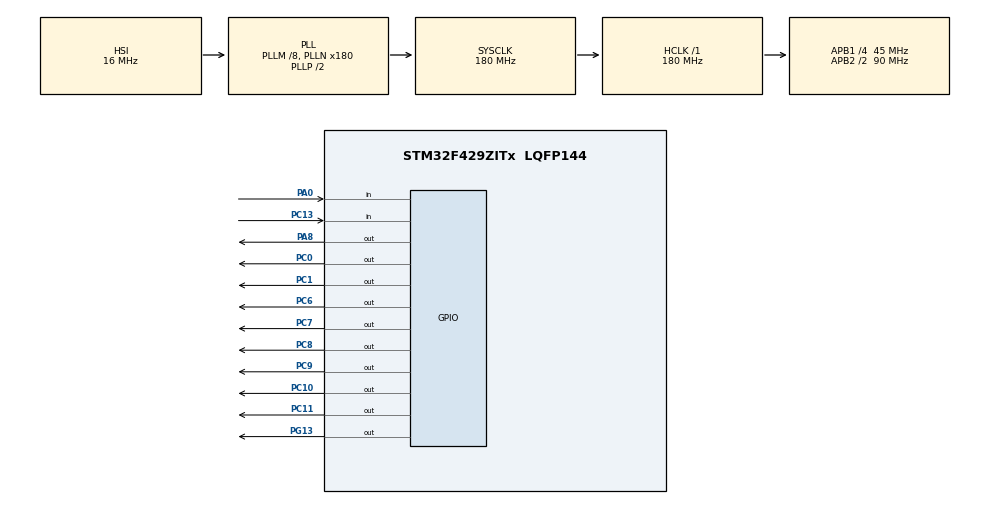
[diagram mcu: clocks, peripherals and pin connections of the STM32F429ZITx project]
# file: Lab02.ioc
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Mcu.Family=STM32F4
Mcu.Name=STM32F429ZITx
Mcu.Package=LQFP144
NVIC.PriorityGroup=NVIC_PRIORITYGROUP_4
PA0/WKUP.Signal=GPIO_Input
PA8.GPIO_ModeDefaultOutputPP=GPIO_MODE_OUTPUT_PP
PA8.PinState=GPIO_PIN_RESET
PA8.Signal=GPIO_Output
PC0.Signal=GPIO_Output
PC1.Signal=GPIO_Output
PC10.PinState=GPIO_PIN_RESET
PC10.Signal=GPIO_Output
PC11.PinState=GPIO_PIN_RESET
PC11.Signal=GPIO_Output
PC13.GPIO_PuPd=GPIO_NOPULL
PC13.Signal=GPIO_Input
PC6.PinState=GPIO_PIN_RESET
PC6.Signal=GPIO_Output
PC7.PinState=GPIO_PIN_RESET
PC7.Signal=GPIO_Output
PC8.GPIO_PuPd=GPIO_NOPULL
PC8.PinState=GPIO_PIN_RESET
PC8.Signal=GPIO_Output
PC9.PinState=GPIO_PIN_RESET
PC9.Signal=GPIO_Output
PG13.GPIO_PuPd=GPIO_NOPULL
PG13.Signal=GPIO_Output
ProjectManager.HeapSize=0x200
ProjectManager.StackSize=0x400
ProjectManager.TargetToolchain=STM32CubeIDE
RCC.48MHZClocksFreq_Value=90000000
RCC.AHBFreq_Value=180000000
RCC.APB1CLKDivider=RCC_HCLK_DIV4
RCC.APB1Freq_Value=45000000
RCC.APB1TimFreq_Value=90000000
RCC.APB2CLKDivider=RCC_HCLK_DIV2
RCC.APB2Freq_Value=90000000
RCC.APB2TimFreq_Value=180000000
RCC.CortexFreq_Value=180000000
RCC.HCLKFreq_Value=180000000
RCC.HSE_VALUE=25000000
RCC.HSI_VALUE=16000000
RCC.LSE_VALUE=32768
RCC.PLLM=8
RCC.PLLN=180
RCC.SYSCLKFreq_VALUE=180000000
RCC.SYSCLKSource=RCC_SYSCLKSOURCE_PLLCLK
RCC.VCOOutputFreq_Value=360000000
board=custom

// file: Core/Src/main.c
/* USER CODE BEGIN Header */
/**
  ******************************************************************************
  * @file           : main.c
  * @brief          : Main program body
  ******************************************************************************
  * @attention
  *
  * <h2><center>&copy; Copyright (c) 2021 STMicroelectronics.
  * All rights reserved.</center></h2>
  *
  * This software component is licensed by ST under BSD 3-Clause license,
  * the "License"; You may not use this file except in compliance with the
  * License. You may obtain a copy of the License at:
  *                        opensource.org/licenses/BSD-3-Clause
  *
  ******************************************************************************
  */
/* USER CODE END Header */
#include "main.h"
#include "gpio.h"

void SystemClock_Config(void);

/* USER CODE BEGIN 0 */
uint8_t num = 0;
uint8_t n = 0;
/* USER CODE END 0 */

int main(void)
{

  /* MCU Configuration--------------------------------------------------------*/

  /* Reset of all peripherals, Initializes the Flash interface and the Systick. */
  HAL_Init();

  /* Configure the system clock */
  SystemClock_Config();

  /* Initialize all configured peripherals */
  MX_GPIO_Init();
  /* USER CODE BEGIN 2 */
  HAL_GPIO_WritePin(GPIOC, GPIO_PIN_0|GPIO_PIN_1|GPIO_PIN_6|GPIO_PIN_7
                              |GPIO_PIN_8|GPIO_PIN_9|GPIO_PIN_10|GPIO_PIN_11, GPIO_PIN_SET);
  /* USER CODE END 2 */

  /* Infinite loop */
  while (1)
  {

    /* USER CODE BEGIN 3 */
//	  /* LAB1-3 */
//	  if(HAL_GPIO_ReadPin(GPIOC,GPIO_PIN_13) == GPIO_PIN_RESET){
//		  /*turn LED Pin8 ON*/
//		  HAL_GPIO_WritePin(GPIOC,GPIO_PIN_8,GPIO_PIN_RESET);
//		  /*check LED Pin8 ON*/
//		  if(HAL_GPIO_ReadPin(GPIOC,GPIO_PIN_8) == GPIO_PIN_RESET){
//			  HAL_GPIO_WritePin(GPIOC,GPIO_PIN_0,GPIO_PIN_RESET);
//		  }
//		  HAL_Delay(1000);
//		  /*turn LED Pin8 OFF*/
//		  HAL_GPIO_WritePin(GPIOC,GPIO_PIN_8,GPIO_PIN_SET);
//		  /*check LED Pin8 OFF*/
//		  if(HAL_GPIO_ReadPin(GPIOC,GPIO_PIN_8) == GPIO_PIN_SET){
//		  			  HAL_GPIO_WritePin(GPIOC,GPIO_PIN_0,GPIO_PIN_SET);
//		  }
//	  }

//	  /* LAB4 */
//	  if(HAL_GPIO_ReadPin(GPIOA,GPIO_PIN_0) == GPIO_PIN_SET){
//		  if(num == 8){
//			  num = 0;
//		  }
//		  num++;
//		  HAL_Delay(500);
//	  }
//	  	  	  if(num == 0)
//	  	  	  	  	  {
//	  	  		HAL_GPIO_WritePin(GPIOC,GPIO_PIN_0,GPIO_PIN_SET);
//	  	  	    HAL_GPIO_WritePin(GPIOC,GPIO_PIN_1,GPIO_PIN_SET);
//	  	  		HAL_GPIO_WritePin(GPIOC,GPIO_PIN_6,GPIO_PIN_SET);
//	  	  	    HAL_GPIO_WritePin(GPIOC,GPIO_PIN_7,GPIO_PIN_SET);
//	  	  	    HAL_GPIO_WritePin(GPIOC,GPIO_PIN_8,GPIO_PIN_SET);
//	  	        HAL_GPIO_WritePin(GPIOC,GPIO_PIN_9,GPIO_PIN_SET);
//	  	  	    HAL_GPIO_WritePin(GPIOC,GPIO_PIN_10,GPIO_PIN_SET);
//	  	  	    HAL_GPIO_WritePin(GPIOC,GPIO_PIN_11,GPIO_PIN_SET);
//	  	  	  	  	  }
//
//	  	  	  if(num == 1)
//	  		  	  	  {
//	  			  HAL_GPIO_WritePin(GPIOC,GPIO_PIN_11,GPIO_PIN_RESET);
//	  			  HAL_GPIO_WritePin(GPIOC,GPIO_PIN_0,GPIO_PIN_SET);
//	  		  	  	  }
//	  		  if(num == 2)
//	  		  		  {
//	  			  HAL_GPIO_WritePin(GPIOC,GPIO_PIN_10,GPIO_PIN_RESET);
//	  			  HAL_GPIO_WritePin(GPIOC,GPIO_PIN_11,GPIO_PIN_SET);
//	  		  		  }
//	  		  if(num == 3)
//	  		  		  {
//	  			  HAL_GPIO_WritePin(GPIOC,GPIO_PIN_9,GPIO_PIN_RESET);
//	  			  HAL_GPIO_WritePin(GPIOC,GPIO_PIN_10,GPIO_PIN_SET);
//	  		  		  }
//	  		  if(num == 4)
//	  		  		  {
//	  			  HAL_GPIO_WritePin(GPIOC,GPIO_PIN_8,GPIO_PIN_RESET);
//	  			  HAL_GPIO_WritePin(GPIOC,GPIO_PIN_9,GPIO_PIN_SET);
//	  		  		  }
//	  		  if(num == 5)
//	  		  		  {
//	  			  HAL_GPIO_WritePin(GPIOC,GPIO_PIN_7,GPIO_PIN_RESET);
//	  			  HAL_GPIO_WritePin(GPIOC,GPIO_PIN_8,GPIO_PIN_SET);
//	  		  		  }
//	  		  if(num == 6)
//	  		  		  {
//	  			  HAL_GPIO_WritePin(GPIOC,GPIO_PIN_6,GPIO_PIN_RESET);
//	  			  HAL_GPIO_WritePin(GPIOC,GPIO_PIN_7,GPIO_PIN_SET);
//	  		  		  }
//	  		  if(num == 7)
//	  		  		  {
//	  			  HAL_GPIO_WritePin(GPIOC,GPIO_PIN_1,GPIO_PIN_RESET);
//	  			  HAL_GPIO_WritePin(GPIOC,GPIO_PIN_6,GPIO_PIN_SET);
//	  		   		  }
//	  		  if(num == 8)
//	  		  		  {
//	  			  HAL_GPIO_WritePin(GPIOC,GPIO_PIN_1,GPIO_PIN_SET);
//	  			  HAL_GPIO_WritePin(GPIOC,GPIO_PIN_0,GPIO_PIN_RESET);
//	  			  	  }
//	  		if(HAL_GPIO_ReadPin(GPIOC,GPIO_PIN_13) == GPIO_PIN_RESET){
//	  		HAL_GPIO_WritePin(GPIOC,GPIO_PIN_0,GPIO_PIN_RESET);
//	  	    HAL_GPIO_WritePin(GPIOC,GPIO_PIN_1,GPIO_PIN_SET);
//	  		HAL_GPIO_WritePin(GPIOC,GPIO_PIN_6,GPIO_PIN_SET);
//	  		HAL_GPIO_WritePin(GPIOC,GPIO_PIN_7,GPIO_PIN_SET);
//	  		HAL_GPIO_WritePin(GPIOC,GPIO_PIN_8,GPIO_PIN_SET);
//	  		HAL_GPIO_WritePin(GPIOC,GPIO_PIN_9,GPIO_PIN_SET);
//	  	    HAL_GPIO_WritePin(GPIOC,GPIO_PIN_10,GPIO_PIN_SET);
//	  		HAL_GPIO_WritePin(GPIOC,GPIO_PIN_11,GPIO_PIN_SET);
//	  		HAL_Delay(500);
//	  		HAL_GPIO_WritePin(GPIOC,GPIO_PIN_1,GPIO_PIN_RESET);
//	  		HAL_GPIO_WritePin(GPIOC,GPIO_PIN_0,GPIO_PIN_SET);
//	  		HAL_Delay(500);
//	  		HAL_GPIO_WritePin(GPIOC,GPIO_PIN_6,GPIO_PIN_RESET);
//	  		HAL_GPIO_WritePin(GPIOC,GPIO_PIN_1,GPIO_PIN_SET);
//	  		HAL_Delay(500);
//	  		HAL_GPIO_WritePin(GPIOC,GPIO_PIN_7,GPIO_PIN_RESET);
//	  		HAL_GPIO_WritePin(GPIOC,GPIO_PIN_6,GPIO_PIN_SET);
//	  		HAL_Delay(500);
//	  		HAL_GPIO_WritePin(GPIOC,GPIO_PIN_8,GPIO_PIN_RESET);
//	  		HAL_GPIO_WritePin(GPIOC,GPIO_PIN_7,GPIO_PIN_SET);
//	  		HAL_Delay(500);
//	  		HAL_GPIO_WritePin(GPIOC,GPIO_PIN_9,GPIO_PIN_RESET);
//	  		HAL_GPIO_WritePin(GPIOC,GPIO_PIN_8,GPIO_PIN_SET);
//	  		HAL_Delay(500);
//	  		HAL_GPIO_WritePin(GPIOC,GPIO_PIN_10,GPIO_PIN_RESET);
//	  		HAL_GPIO_WritePin(GPIOC,GPIO_PIN_9,GPIO_PIN_SET);
//	  		HAL_Delay(500);
//	  		HAL_GPIO_WritePin(GPIOC,GPIO_PIN_10,GPIO_PIN_SET);
//	  		HAL_GPIO_WritePin(GPIOC,GPIO_PIN_11,GPIO_PIN_RESET);
//	  		HAL_Delay(500);
//	  		num = 0;
//	  		  }
//
//	  for(n=0;n<=2;n++){
//		  GPIOC -> BSRR = 0x07000000;
//		  HAL_Delay(500);
//		  GPIOC -> BSRR = 0x00000400 >> n;
//		  HAL_Delay(500);
//	  }
	  GPIOC -> BSRR = 0x07000000;
	  HAL_Delay(500);
	  GPIOC -> BSRR = 0x00000700;
	  HAL_Delay(500);
  }

  /* USER CODE END 3 */
}

void SystemClock_Config(void)
{
  RCC_OscInitTypeDef RCC_OscInitStruct = {0};
  RCC_ClkInitTypeDef RCC_ClkInitStruct = {0};

  /** Configure the main internal regulator output voltage
  */
  __HAL_RCC_PWR_CLK_ENABLE();
  __HAL_PWR_VOLTAGESCALING_CONFIG(PWR_REGULATOR_VOLTAGE_SCALE1);
  /** Initializes the RCC Oscillators according to the specified parameters
  * in the RCC_OscInitTypeDef structure.
  */
  RCC_OscInitStruct.OscillatorType = RCC_OSCILLATORTYPE_HSI;
  RCC_OscInitStruct.HSIState = RCC_HSI_ON;
  RCC_OscInitStruct.HSICalibrationValue = RCC_HSICALIBRATION_DEFAULT;
  RCC_OscInitStruct.PLL.PLLState = RCC_PLL_ON;
  RCC_OscInitStruct.PLL.PLLSource = RCC_PLLSOURCE_HSI;
  RCC_OscInitStruct.PLL.PLLM = 8;
  RCC_OscInitStruct.PLL.PLLN = 180;
  RCC_OscInitStruct.PLL.PLLP = RCC_PLLP_DIV2;
  RCC_OscInitStruct.PLL.PLLQ = 4;
  if (HAL_RCC_OscConfig(&RCC_OscInitStruct) != HAL_OK)
  {
    Error_Handler();
  }
  /** Activate the Over-Drive mode
  */
  if (HAL_PWREx_EnableOverDrive() != HAL_OK)
  {
    Error_Handler();
  }
  /** Initializes the CPU, AHB and APB buses clocks
  */
  RCC_ClkInitStruct.ClockType = RCC_CLOCKTYPE_HCLK|RCC_CLOCKTYPE_SYSCLK
                              |RCC_CLOCKTYPE_PCLK1|RCC_CLOCKTYPE_PCLK2;
  RCC_ClkInitStruct.SYSCLKSource = RCC_SYSCLKSOURCE_PLLCLK;
  RCC_ClkInitStruct.AHBCLKDivider = RCC_SYSCLK_DIV1;
  RCC_ClkInitStruct.APB1CLKDivider = RCC_HCLK_DIV4;
  RCC_ClkInitStruct.APB2CLKDivider = RCC_HCLK_DIV2;

  if (HAL_RCC_ClockConfig(&RCC_ClkInitStruct, FLASH_LATENCY_5) != HAL_OK)
  {
    Error_Handler();
  }
}

void Error_Handler(void)
{
  __disable_irq();
  while (1)
  {
  }
}

/************************ (C) COPYRIGHT STMicroelectronics *****END OF FILE****/
